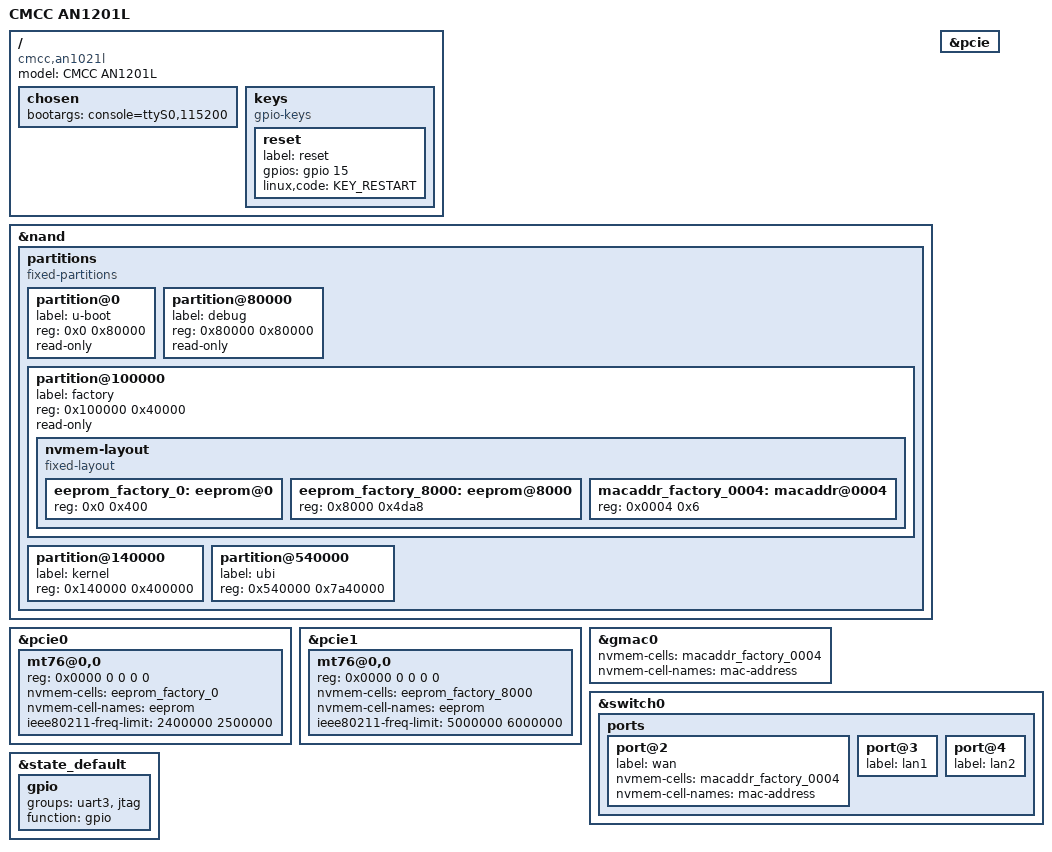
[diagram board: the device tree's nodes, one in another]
#include "mt7621.dtsi"

#include <dt-bindings/gpio/gpio.h>
#include <dt-bindings/input/input.h>
#include <dt-bindings/leds/common.h>

/ {
	compatible = "cmcc,an1021l", "mediatek,mt7621-soc";
	model = "CMCC AN1201L";

	chosen {
		bootargs = "console=ttyS0,115200";
	};

	keys {
		compatible = "gpio-keys";

		reset {
			label = "reset";
			gpios = <&gpio 15 GPIO_ACTIVE_HIGH>;
			linux,code = <KEY_RESTART>;
		};
	};
};

&nand {
	status = "okay";

	partitions {
		compatible = "fixed-partitions";
		#address-cells = <1>;
		#size-cells = <1>;

		partition@0 {
			label = "u-boot";
			reg = <0x0 0x80000>;
			read-only;
		};

		partition@80000 {
			label = "debug";
			reg = <0x80000 0x80000>;
			read-only;
		};

		partition@100000 {
			label = "factory";
			reg = <0x100000 0x40000>;
			read-only;

			nvmem-layout {
				compatible = "fixed-layout";
				#address-cells = <1>;
				#size-cells = <1>;

				eeprom_factory_0: eeprom@0 {
					reg = <0x0 0x400>;
				};

				eeprom_factory_8000: eeprom@8000 {
					reg = <0x8000 0x4da8>;
				};

				macaddr_factory_0004: macaddr@0004 {
					reg = <0x0004 0x6>;
				};
			};
		};

		partition@140000 {
			label = "kernel";
			reg = <0x140000 0x400000>;
		};

		partition@540000 {
			label = "ubi";
			reg = <0x540000 0x7a40000>;
		};
	};
};

&pcie {
	status = "okay";
};

&pcie0 {
	mt76@0,0 {
		reg = <0x0000 0 0 0 0>;
		nvmem-cells = <&eeprom_factory_0>;
		nvmem-cell-names = "eeprom";
		ieee80211-freq-limit = <2400000 2500000>;
	};
};

&pcie1 {
	mt76@0,0 {
		reg = <0x0000 0 0 0 0>;
		nvmem-cells = <&eeprom_factory_8000>;
		nvmem-cell-names = "eeprom";
		ieee80211-freq-limit = <5000000 6000000>;
	};
};

&gmac0 {
	nvmem-cells = <&macaddr_factory_0004>;
	nvmem-cell-names = "mac-address";
};

&switch0 {
	ports {
		port@2 {
			status = "okay";
			label = "wan";
			nvmem-cells = <&macaddr_factory_0004>;
			nvmem-cell-names = "mac-address";
		};

		port@3 {
			status = "okay";
			label = "lan1";
		};

		port@4 {
			status = "okay";
			label = "lan2";
		};
	};
};

&state_default {
	gpio {
		groups = "uart3", "jtag";
		function = "gpio";
	};
};
